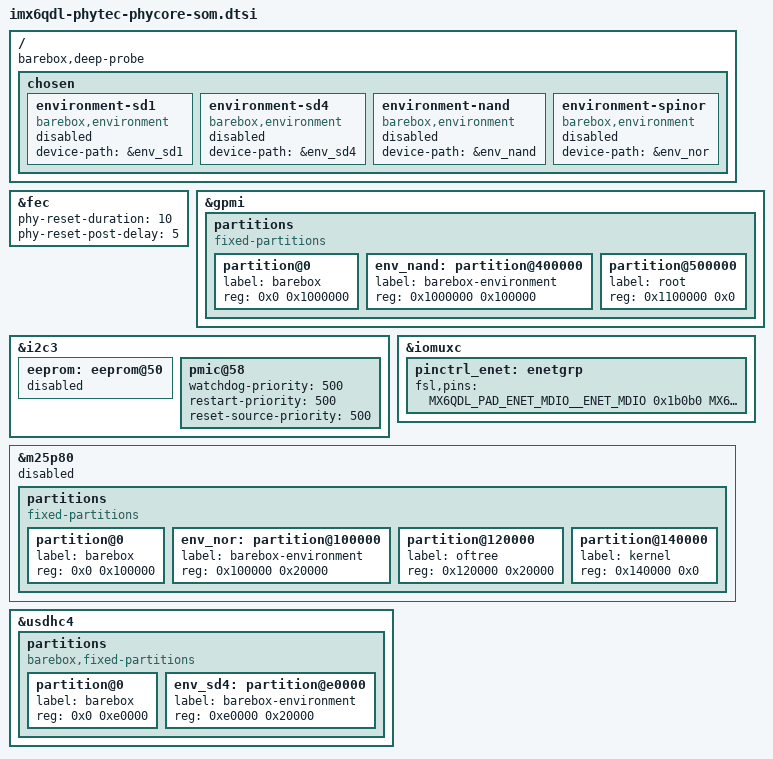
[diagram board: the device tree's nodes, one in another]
// SPDX-License-Identifier: (GPL-2.0-or-later)
/*
 * Copyright (C) 2015 PHYTEC Messtechnik GmbH
 * Author: Christian Hemp <c.hemp@phytec.de>
 */

#include <arm/nxp/imx/imx6qdl-phytec-phycore-som.dtsi>
#include <dt-bindings/gpio/gpio.h>

/ {
	barebox,deep-probe;
	chosen {
		environment-sd1 {
			compatible = "barebox,environment";
			device-path = &env_sd1;
			status = "disabled";
		};

		environment-sd4 {
			compatible = "barebox,environment";
			device-path = &env_sd4;
			status = "disabled";
		};

		environment-nand {
			compatible = "barebox,environment";
			device-path = &env_nand;
			status = "disabled";
		};

		environment-spinor {
			compatible = "barebox,environment";
			device-path = &env_nor;
			status = "disabled";
		};
	};
};

/delete-node/ &{/memory@10000000};

&fec {
	/delete-property/ phy-supply;
	phy-reset-duration = <10>; /* in msecs */
	phy-reset-post-delay = <5>;
};

&gpmi {
	partitions {
		compatible = "fixed-partitions";
		#address-cells = <1>;
		#size-cells = <1>;

		partition@0 {
			label = "barebox";
			reg = <0x0 0x1000000>;
		};

		env_nand: partition@400000 {
			label = "barebox-environment";
			reg = <0x1000000 0x100000>;
		};

		partition@500000 {
			label = "root";
			reg = <0x1100000 0x0>;
		};
	};
};

&i2c3 {
	eeprom: eeprom@50 {
		status = "disabled";
	};

	pmic@58 {
		watchdog-priority = <500>;
		restart-priority = <500>;
		reset-source-priority = <500>;
	};
};

&iomuxc {
	pinctrl_enet: enetgrp {
		fsl,pins = <
			MX6QDL_PAD_ENET_MDIO__ENET_MDIO		0x1b0b0
			MX6QDL_PAD_ENET_MDC__ENET_MDC		0x1b0b0
			MX6QDL_PAD_RGMII_TXC__RGMII_TXC		0x1b020
			MX6QDL_PAD_RGMII_TD0__RGMII_TD0		0x1b018
			MX6QDL_PAD_RGMII_TD1__RGMII_TD1		0x1b018
			MX6QDL_PAD_RGMII_TD2__RGMII_TD2		0x1b018
			MX6QDL_PAD_RGMII_TD3__RGMII_TD3		0x1b018
			MX6QDL_PAD_RGMII_TX_CTL__RGMII_TX_CTL	0x1b018
			MX6QDL_PAD_ENET_REF_CLK__ENET_TX_CLK	0x180b0
			MX6QDL_PAD_RGMII_RXC__RGMII_RXC		0x180b0
			MX6QDL_PAD_RGMII_RD0__RGMII_RD0		0x180b0
			MX6QDL_PAD_RGMII_RD1__RGMII_RD1		0x180b0
			MX6QDL_PAD_RGMII_RD2__RGMII_RD2		0x180b0
			MX6QDL_PAD_RGMII_RD3__RGMII_RD3		0x180b0
			MX6QDL_PAD_RGMII_RX_CTL__RGMII_RX_CTL	0x180b0
			MX6QDL_PAD_ENET_TX_EN__ENET_TX_EN	0x1b0b0
			MX6QDL_PAD_SD2_DAT1__GPIO1_IO14		0x1b0b0
		>;
	};
};

&m25p80 {
	status = "disabled";

	partitions {
		compatible = "fixed-partitions";
		#address-cells = <1>;
		#size-cells = <1>;

		partition@0 {
			label = "barebox";
			reg = <0x0 0x100000>;
		};

		env_nor: partition@100000 {
			label = "barebox-environment";
			reg = <0x100000 0x20000>;
		};

		partition@120000 {
			label = "oftree";
			reg = <0x120000 0x20000>;
		};

		partition@140000 {
			label = "kernel";
			reg = <0x140000 0x0>;
		};
	};
};

&usdhc4 {
	partitions {
		compatible = "barebox,fixed-partitions";
		#address-cells = <1>;
		#size-cells = <1>;

		partition@0 {
			label = "barebox";
			reg = <0x0 0xe0000>;
		};

		env_sd4: partition@e0000 {
			label = "barebox-environment";
			reg = <0xe0000 0x20000>;
		};
	};
};
